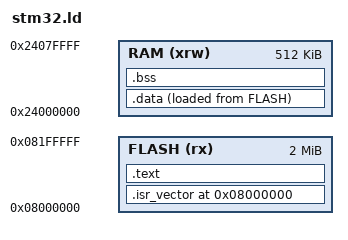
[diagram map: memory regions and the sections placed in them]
/* stm32 linker */

ENTRY(Reset_Handler)

_estack = ORIGIN(RAM) + LENGTH(RAM);

MEMORY
{
    FLASH (rx)  : ORIGIN = 0x08000000, LENGTH = 2048K
    RAM   (xrw) : ORIGIN = 0x24000000, LENGTH = 512K
}

SECTIONS
{
    /* Force starts exactly at ORIGIN(FLASH) */
    .isr_vector 0x08000000 :
    {
        . = ALIGN(4);
        KEEP(*(.isr_vector))
        . = ALIGN(4);
    } > FLASH

    .text :
    {
        . = ALIGN(4);
        *(.text)
        *(.text*)
        *(.rodata)
        *(.rodata*)
        . = ALIGN(4);
        _etext = .;
    } > FLASH

    _sidata = LOADADDR(.data);

    .data :
    {
        . = ALIGN(4);
        _sdata = .;
        *(.data)
        *(.data*)
        . = ALIGN(4);
        _edata = .;
    } > RAM AT > FLASH

    .bss :
    {
        . = ALIGN(4);
        _sbss = .;
        *(.bss)
        *(.bss*)
        *(COMMON)
        . = ALIGN(4);
        _ebss = .;
    } > RAM

    . = ALIGN(8);
    _end = .;
}
